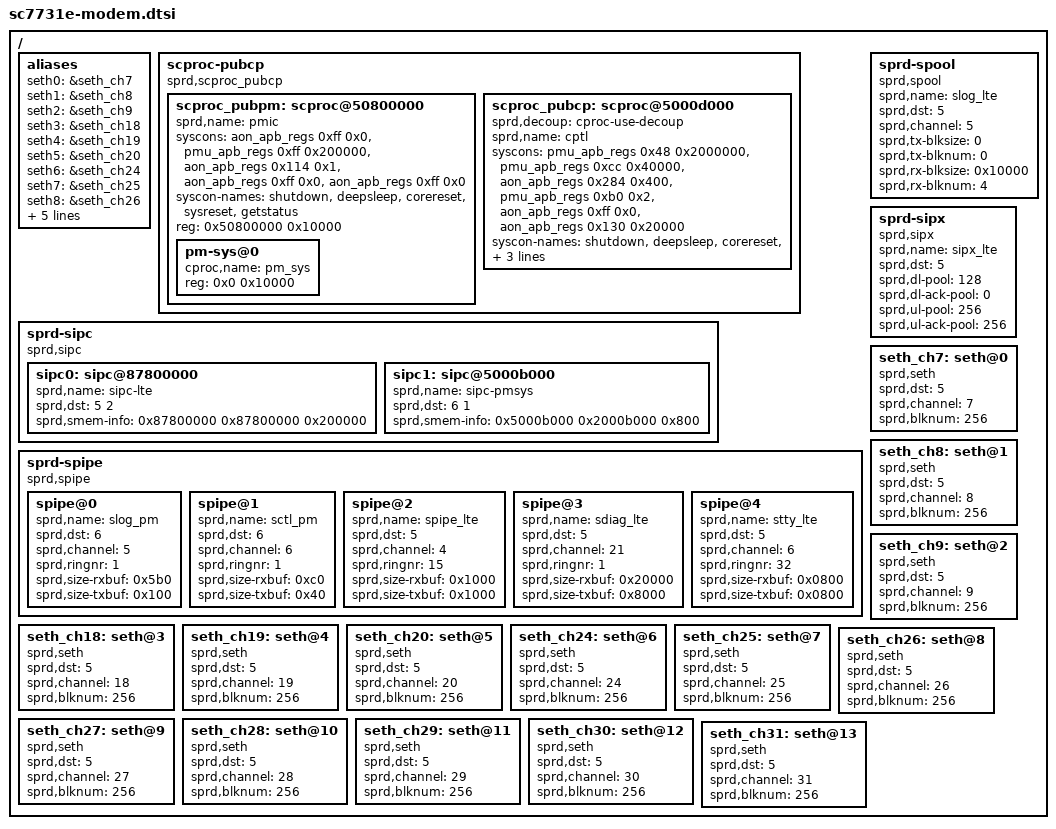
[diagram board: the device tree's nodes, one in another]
/*
 * Spreadtrum SC7731E modem board DTSI file
 * These dt is used for modem drivers
 *
 * Copyright (C) 2019, Spreadtrum Communications Inc.
 *
 * This file is licensed under a dual GPLv2 or X11 license.
 */

/ {
	aliases {
		seth0 = &seth_ch7;
		seth1 = &seth_ch8;
		seth2 = &seth_ch9;
		seth3 = &seth_ch18;
		seth4 = &seth_ch19;
		seth5 = &seth_ch20;
		seth6 = &seth_ch24;
		seth7 = &seth_ch25;
		seth8 = &seth_ch26;
		seth9 = &seth_ch27;
		seth10 = &seth_ch28;
		seth11 = &seth_ch29;
		seth12 = &seth_ch30;
		seth13 = &seth_ch31;
	};

	scproc-pubcp {
		compatible = "sprd,scproc_pubcp";
		#address-cells = <1>;
		#size-cells = <1>;
		ranges;
		scproc_pubpm: scproc@50800000 {
			sprd,name = "pmic";
			/* 0xff is invaild register offset */
			syscons = <&aon_apb_regs 0xff 0x0>,
					<&pmu_apb_regs 0xff 0x200000>,
					<&aon_apb_regs 0x114 0x1>,
					<&aon_apb_regs 0xff 0x0>,
					<&aon_apb_regs 0xff 0x0>;
			syscon-names = "shutdown", "deepsleep", "corereset",
						"sysreset", "getstatus";
			reg = <0x50800000 0x10000>;
			#address-cells = <1>;
			#size-cells = <1>;
			/* segnr=1 */
			ranges = <0x0 0x50800000 0x10000>;
			pm-sys@0 {
				cproc,name = "pm_sys";
				reg = <0x0 0x10000>;
			};
		};

		scproc_pubcp: scproc@5000d000 {
			sprd,decoup = "cproc-use-decoup";
			sprd,name = "cptl";
			/* 0xff is invaild register offset */
			syscons = <&pmu_apb_regs 0x48 0x2000000>,
					<&pmu_apb_regs 0xcc 0x40000>,
					<&aon_apb_regs 0x284 0x400>,
					<&pmu_apb_regs 0xb0 0x2>,
					<&aon_apb_regs 0xff 0x0>,
					<&aon_apb_regs 0x130 0x20000>;
			syscon-names = "shutdown", "deepsleep", "corereset",
					"sysreset", "getstatus", "dspreset";
			reg = <0x5000d000 0x1000>;
			interrupts = <GIC_SPI 83 0x0>;
		};
	};

	sprd-sipc {
		compatible = "sprd,sipc";
		sipc0: sipc@87800000 {
			sprd,name = "sipc-lte";
			sprd,dst = <5 2>; /* <dst core-id> */
			/* <ap-addr dst-maped-addr size> */
			sprd,smem-info = <0x87800000 0x87800000 0x200000>;
		};

		sipc1: sipc@5000b000 {
			sprd,name = "sipc-pmsys";
			sprd,dst = <6 1>; /* <dst core-id> */
			/* <ap-addr dst-maped-addr size> */
			sprd,smem-info = <0x5000b000 0x2000b000 0x800>;
		};
	};

	sprd-spipe {
		compatible = "sprd,spipe";

		spipe@0 {
			sprd,name = "slog_pm";
			sprd,dst = <6>;
			sprd,channel = <5>;
			sprd,ringnr = <1>;
			sprd,size-rxbuf = <0x5b0>;
			sprd,size-txbuf = <0x100>;
		};

		spipe@1 {
			sprd,name = "sctl_pm";
			sprd,dst = <6>;
			sprd,channel = <6>;
			sprd,ringnr = <1>;
			sprd,size-rxbuf = <0xc0>;
			sprd,size-txbuf = <0x40>;
		};

		spipe@2 {
			sprd,name = "spipe_lte";
			sprd,dst = <5>;
			sprd,channel = <4>;
			sprd,ringnr = <15>;
			sprd,size-rxbuf = <0x1000>; /* 4*1024 */
			sprd,size-txbuf = <0x1000>; /* 4*1024 */
		};

		spipe@3 {
			sprd,name = "sdiag_lte";
			sprd,dst = <5>;
			sprd,channel = <21>;
			sprd,ringnr = <1>;
			sprd,size-rxbuf = <0x20000>; /* 256*1024*/
			sprd,size-txbuf = <0x8000>; /* 32*1024 */
		};

		spipe@4 {
			sprd,name = "stty_lte";
			sprd,dst = <5>;
			sprd,channel = <6>;
			sprd,ringnr = <32>;
			sprd,size-rxbuf = <0x0800>; /* 2*1024*/
			sprd,size-txbuf = <0x0800>; /* 2*1024 */
		};
	};

	sprd-spool {
		compatible = "sprd,spool";
		sprd,name = "slog_lte";
		sprd,dst = <5>;
		sprd,channel = <5>;
		sprd,tx-blksize = <0>;
		sprd,tx-blknum = <0>;
		sprd,rx-blksize = <0x10000>; /* 64k*/
		sprd,rx-blknum = <4>;
	};

	sprd-sipx {
		compatible = "sprd,sipx";
		sprd,name = "sipx_lte";
		sprd,dst = <5>;
		sprd,dl-pool = <128>;
		sprd,dl-ack-pool = <0>;
		sprd,ul-pool = <256>;
		sprd,ul-ack-pool = <256>;
	};

	seth_ch7: seth@0 {
		compatible = "sprd,seth";
		sprd,dst = <5>;
		sprd,channel = <7>;
		sprd,blknum = <256>;
	};

	seth_ch8: seth@1 {
		compatible = "sprd,seth";
		sprd,dst = <5>;
		sprd,channel = <8>;
		sprd,blknum = <256>;
	};

	seth_ch9: seth@2 {
		compatible = "sprd,seth";
		sprd,dst = <5>;
		sprd,channel = <9>;
		sprd,blknum = <256>;
	};

	seth_ch18: seth@3 {
		compatible = "sprd,seth";
		sprd,dst = <5>;
		sprd,channel = <18>;
		sprd,blknum = <256>;
	};

	seth_ch19: seth@4 {
		compatible = "sprd,seth";
		sprd,dst = <5>;
		sprd,channel = <19>;
		sprd,blknum = <256>;
	};

	seth_ch20: seth@5 {
		compatible = "sprd,seth";
		sprd,dst = <5>;
		sprd,channel = <20>;
		sprd,blknum = <256>;
	};

	seth_ch24: seth@6 {
		compatible = "sprd,seth";
		sprd,dst = <5>;
		sprd,channel = <24>;
		sprd,blknum = <256>;
	};

	seth_ch25: seth@7 {
		compatible = "sprd,seth";
		sprd,dst = <5>;
		sprd,channel = <25>;
		sprd,blknum = <256>;
	};

	seth_ch26: seth@8 {
		compatible = "sprd,seth";
		sprd,dst = <5>;
		sprd,channel = <26>;
		sprd,blknum = <256>;
	};

	seth_ch27: seth@9 {
		compatible = "sprd,seth";
		sprd,dst = <5>;
		sprd,channel = <27>;
		sprd,blknum = <256>;
	};

	seth_ch28: seth@10 {
		compatible = "sprd,seth";
		sprd,dst = <5>;
		sprd,channel = <28>;
		sprd,blknum = <256>;
	};

	seth_ch29: seth@11 {
		compatible = "sprd,seth";
		sprd,dst = <5>;
		sprd,channel = <29>;
		sprd,blknum = <256>;
	};

	seth_ch30: seth@12 {
		compatible = "sprd,seth";
		sprd,dst = <5>;
		sprd,channel = <30>;
		sprd,blknum = <256>;
	};

	seth_ch31: seth@13 {
		compatible = "sprd,seth";
		sprd,dst = <5>;
		sprd,channel = <31>;
		sprd,blknum = <256>;
	};
};
